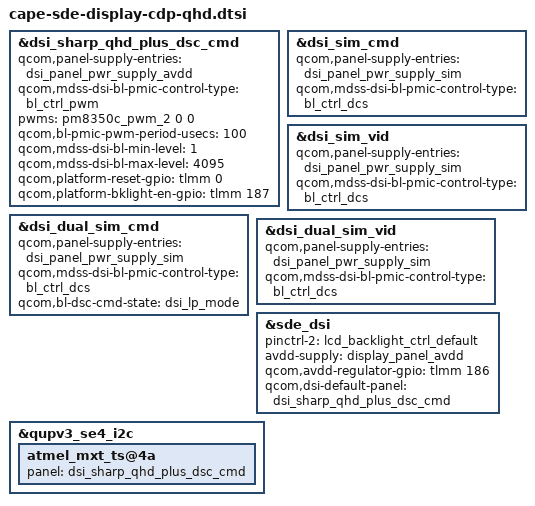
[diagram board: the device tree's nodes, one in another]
#include "cape-sde-display.dtsi"

&dsi_sharp_qhd_plus_dsc_cmd {
	qcom,panel-supply-entries = <&dsi_panel_pwr_supply_avdd>;
	qcom,mdss-dsi-bl-pmic-control-type = "bl_ctrl_pwm";
	pwms = <&pm8350c_pwm_2 0 0>;
	qcom,bl-pmic-pwm-period-usecs = <100>;
	qcom,mdss-dsi-bl-min-level = <1>;
	qcom,mdss-dsi-bl-max-level = <4095>;
	qcom,platform-reset-gpio = <&tlmm 0 0>;
	qcom,platform-bklight-en-gpio = <&tlmm 187 0>;
};

&dsi_sim_cmd {
	qcom,panel-supply-entries = <&dsi_panel_pwr_supply_sim>;
	qcom,mdss-dsi-bl-pmic-control-type = "bl_ctrl_dcs";
};

&dsi_sim_vid {
	qcom,panel-supply-entries = <&dsi_panel_pwr_supply_sim>;
	qcom,mdss-dsi-bl-pmic-control-type = "bl_ctrl_dcs";
};

&dsi_dual_sim_cmd {
	qcom,panel-supply-entries = <&dsi_panel_pwr_supply_sim>;
	qcom,mdss-dsi-bl-pmic-control-type = "bl_ctrl_dcs";
	qcom,bl-dsc-cmd-state = "dsi_lp_mode";
};

&dsi_dual_sim_vid {
	qcom,panel-supply-entries = <&dsi_panel_pwr_supply_sim>;
	qcom,mdss-dsi-bl-pmic-control-type = "bl_ctrl_dcs";
};

&sde_dsi {
	pinctrl-names = "panel_active", "panel_suspend", "pwm_pin";
	pinctrl-2 = <&lcd_backlight_ctrl_default>;
	avdd-supply = <&display_panel_avdd>;
	qcom,avdd-regulator-gpio = <&tlmm 186 0>;
	qcom,dsi-default-panel = <&dsi_sharp_qhd_plus_dsc_cmd>;
};

&qupv3_se4_i2c {
	atmel_mxt_ts@4a {
		panel = <&dsi_sharp_qhd_plus_dsc_cmd>;
	};
};

